VERSION "1.1"

NS_ :

BS_:

BU_: VCU PCU BMS PDU

BO_ 512 COMMAND_FRAME_BMS: 8 VCU
 SG_ VCU_STATE_REQUEST : 5|3@1+ (1,0) [0|7] ""  BMS

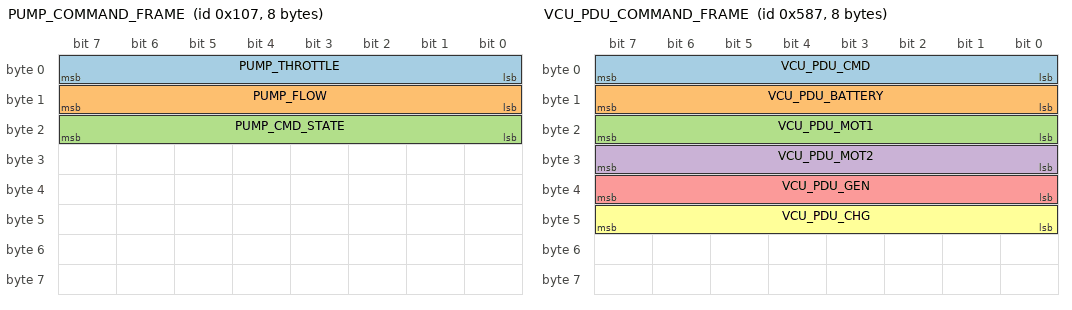
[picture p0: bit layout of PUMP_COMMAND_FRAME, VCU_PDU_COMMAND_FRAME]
BO_ 263 PUMP_COMMAND_FRAME: 8 VCU
 SG_ PUMP_THROTTLE : 0|8@1+ (1,0) [0|100] "%"  VCU
 SG_ PUMP_FLOW : 8|8@1+ (0.1,0) [0|25.5] "L/min"  VCU
 SG_ PUMP_CMD_STATE : 16|8@1+ (1,0) [0|255] ""  VCU

BO_ 1543 CCU_ZCU_COMMAND_FRAME: 8 VCU
 SG_ CCU_CMD : 0|8@1+ (1,0) [0|1] ""  VCU

BO_ 1831 VCU_PCU_COMMAND_FRAME: 8 VCU
 SG_ VCU_PCU_DERATING_MODE : 0|1@1+ (1,0) [0|1] ""  PCU
 SG_ VCU_PCU_MAINTENANCE_MODE : 1|1@1+ (1,0) [0|1] ""  PCU
 SG_ VCU_PCU_MODE_ECO_SPORT : 2|1@1+ (1,0) [0|1] ""  PCU
 SG_ VCU_PCU_BOOST_MODE : 3|1@1+ (1,0) [0|1] ""  PCU
 SG_ VCU_PCU_BIST_mode : 4|1@1+ (1,0) [0|1] ""  PCU
 SG_ VCU_PCU_BRAKE : 5|1@1+ (1,0) [0|1] ""  PCU
 SG_ VCU_PCU_MODE_START_STOP : 6|1@1+ (1,0) [0|1] ""  PCU
 SG_ VCU_PCU_FORCED_MODE : 7|1@1+ (1,0) [0|1] ""  PCU
 SG_ VCU_PCU_CTRL_FORCEDPUMP : 8|4@1+ (1,0) [0|15] ""  PCU
 SG_ VCU_PCU_TRIM_DOWN_COMMAND : 12|1@1+ (1,0) [0|1] ""  PCU
 SG_ VCU_PCU_TRIM_UP_COMMAND : 13|1@1+ (1,0) [0|1] ""  PCU
 SG_ VCU_PCU_CTRL_JAKETRIM_SEL : 14|1@1+ (1,0) [0|1] ""  PCU
 SG_ VCU_PCU_LED : 15|1@1+ (1,0) [0|1] ""  PCU
 SG_ VCU_PCU_THROTTLE : 16|7@1+ (1,0) [0|100] "%"  PCU
 SG_ VCU_PCU_WATER_DETECTED : 23|1@1+ (1,0) [0|1] ""  PCU
 SG_ VCU_PCU_DRIVE_SELECT : 24|4@1+ (1,0) [0|15] ""  PCU
 SG_ VCU_PCU_IGN : 28|1@1+ (1,0) [0|1] ""  PCU
 SG_ VCU_PCU_DRIVE_CHARGE_STATE : 29|1@1+ (1,0) [0|1] ""  PCU
 SG_ VCU_PCU_kill : 30|1@1+ (1,0) [0|1] ""  PCU
 SG_ VCU_PCU_HVIL : 31|1@1+ (1,0) [0|1] ""  PCU
 SG_ VCU_PCU_UV_LIMIT : 32|16@1+ (0.1,0) [0|6553.5] "V"  PCU
 SG_ VCU_PCU_MAXCUR_LIMIT : 48|16@1+ (1,0) [0|65535] "A"  PCU

BO_ 1415 VCU_PDU_COMMAND_FRAME: 8 VCU
 SG_ VCU_PDU_CMD : 0|8@1+ (1,0) [0|1] ""  PDU
 SG_ VCU_PDU_BATTERY : 8|8@1+ (1,0) [0|1] ""  PDU
 SG_ VCU_PDU_MOT1 : 16|8@1+ (1,0) [0|1] ""  PDU
 SG_ VCU_PDU_MOT2 : 24|8@1+ (1,0) [0|1] ""  PDU
 SG_ VCU_PDU_GEN : 32|8@1+ (1,0) [0|1] ""  PDU
 SG_ VCU_PDU_CHG : 40|8@1+ (1,0) [0|1] ""  PDU

VAL_ 1415 VCU_PDU_CMD 0 "NoCmd" 1 "Switch" ;
VAL_ 1415 VCU_PDU_BATTERY 0 "Open" 1 "Close" ;
VAL_ 1415 VCU_PDU_MOT1 0 "Open" 1 "Close" ;
VAL_ 1415 VCU_PDU_MOT2 0 "Open" 1 "Close" ;
VAL_ 1415 VCU_PDU_GEN 0 "Open" 1 "Close" ;
VAL_ 1415 VCU_PDU_CHG 0 "Open" 1 "Close" ;
